AUTOSAR XML (schema 00050)
package /FCADT/ComponentTypes
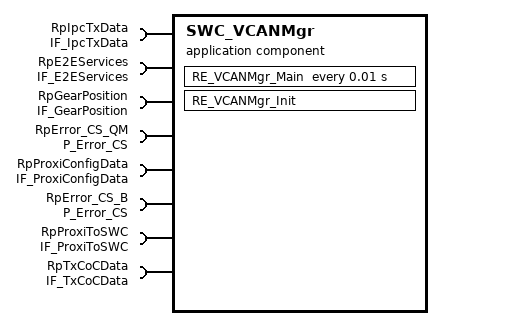
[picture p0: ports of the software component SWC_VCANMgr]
  application sw component type SWC_VCANMgr
    8 x require port:
      RpIpcTxData: client-com-spec=IPC_Write_v, required-interface=IF_IpcTxData
      RpE2EServices: required-com-specs=[ME_E2E_Check, ME_E2E_Protect], required-interface=IF_E2EServices
      RpGearPosition: nonqueued-receiver-com-spec{data-element=GearValue, filter=data-filter-type=ALWAYS, init-value=0}, required-interface=IF_GearPosition
      RpError_CS_QM: client-com-spec=ReportErrorStatus1_0_QM, required-interface=P_Error_CS
      RpProxiConfigData: nonqueued-receiver-com-spec{data-element=ProxiData, filter=data-filter-type=ALWAYS}, required-interface=IF_ProxiConfigData
      RpError_CS_B: client-com-spec=ReportErrorStatus1_0_B, required-interface=P_Error_CS
      RpProxiToSWC: required-interface=IF_ProxiToSWC
        required-com-specs:
          data-element=TyreSz_u16, filter=data-filter-type=ALWAYS
          data-element=SurroundViewCam_u8, filter=data-filter-type=ALWAYS
      RpTxCoCData: required-interface=IF_TxCoCData
        required-com-specs:
          data-element=TRSCM_FD_1_flag, filter=data-filter-type=ALWAYS
          data-element=CVPAM_FD_Info_flag, filter=data-filter-type=ALWAYS
    behavior SWC_VCANMgr_InternalBehavior: data-type-mapping=[defaultDataTypeMappingSet_CPFS, defaultDataTypeMappingSet_CPFS, defaultDataTypeMappingSet_CPFS, defaultDataTypeMappingSet_CPFS, defaultDataTypeMappingSet_CPFS], handle-termination-and-restart=NO-SUPPORT
      init event InitEvent: start-on-event=RE_VCANMgr_Init
      timing event TMT_RE_VCANMgr_Main: start-on-event=RE_VCANMgr_Main, period=0.01
      port-api-options:
        enable-take-address=false, error-handling=NO-TRANSFORMER-ERROR-HANDLING, indirect-api=false, port=RpE2EServices
        enable-take-address=false, error-handling=NO-TRANSFORMER-ERROR-HANDLING, indirect-api=false, port=RpIpcTxData
      runnable RE_VCANMgr_Init
      runnable RE_VCANMgr_Main
        data-receive-point-by-arguments:
          6 x access:
            REC_RpGearPosition_GearValue: accessed-variable=RpGearPosition.GearValue
            REC_RpProxiConfigData_ProxiData: accessed-variable=RpProxiConfigData.ProxiData
            REC_RpProxiToSWC_SurroundViewCam_u8: accessed-variable=RpProxiToSWC.SurroundViewCam_u8
            REC_RpProxiToSWC_TyreSz_u16: accessed-variable=RpProxiToSWC.TyreSz_u16
            REC_RpTxCoCData_CVPAM_FD_Info_flag: accessed-variable=RpTxCoCData.CVPAM_FD_Info_flag
            REC_RpTxCoCData_TRSCM_FD_1_flag: accessed-variable=RpTxCoCData.TRSCM_FD_1_flag
        5 x sync call:
          SC_RpE2EServices_ME_E2E_Check: operation=RpE2EServices.ME_E2E_Check
          SC_RpE2EServices_ME_E2E_Protect: operation=RpE2EServices.ME_E2E_Protect
          SC_RpError_CS_B_ReportErrorStatus1_0_B: operation=RpError_CS_B.ReportErrorStatus1_0_B
          SC_RpError_CS_QM_ReportErrorStatus1_0_QM: operation=RpError_CS_QM.ReportErrorStatus1_0_QM
          SC_RpIpcTxData_IPC_Write_v: operation=RpIpcTxData.IPC_Write_v
  swc implementation SWC_VCANMgr_Implementation: programming-language=C, vendor-id=0, behavior=SWC_VCANMgr_InternalBehavior
    code-descriptors:
      code Default: artifact-descriptors=autosar-engineering-object=category=SWSRC
